AUTOSAR XML (schema 00051)
package /SharedElements/PortInterfaces/ClientServer
  client server interface InProc_OBCSt_SR
    4 x operation:
      OBC00S  # Turn switch sensor position [left, off, right]
      OBC01S  # Turn switch sensor position [left, off, right]
      OBC10S  # Turn switch sensor position [left, off, right]
      OBC11S  # Turn switch sensor position [left, off, right]
package /SharedElements/PortInterfaces/NvData
  nv data interface InProc_OBCErPrmntActvDschrg_SR
    nv-datas:
      4 x data:
        OBC00EPAD  # Turn switch sensor position [left, off, right]
        OBC01EPAD  # Turn switch sensor position [left, off, right]
        OBC10EPAD  # Turn switch sensor position [left, off, right]
        OBC11EPAD  # Turn switch sensor position [left, off, right]
  nv data interface NV_BCBStatDrsn_NVD
    nv-datas:
      data BCBStatDrsn_NvData  # Turn switch sensor position [left, off, right]
package /SharedElements/PortInterfaces/Parameter
  parameter interface GC_ActvDshgStrtTm_PI
    parameter data prototype ADST  # Turn switch sensor position [left, off, right]
package /SharedElements/PortInterfaces/Trigger
  trigger interface TriggerInterface
package /SwComponentTypes/ApplSWC
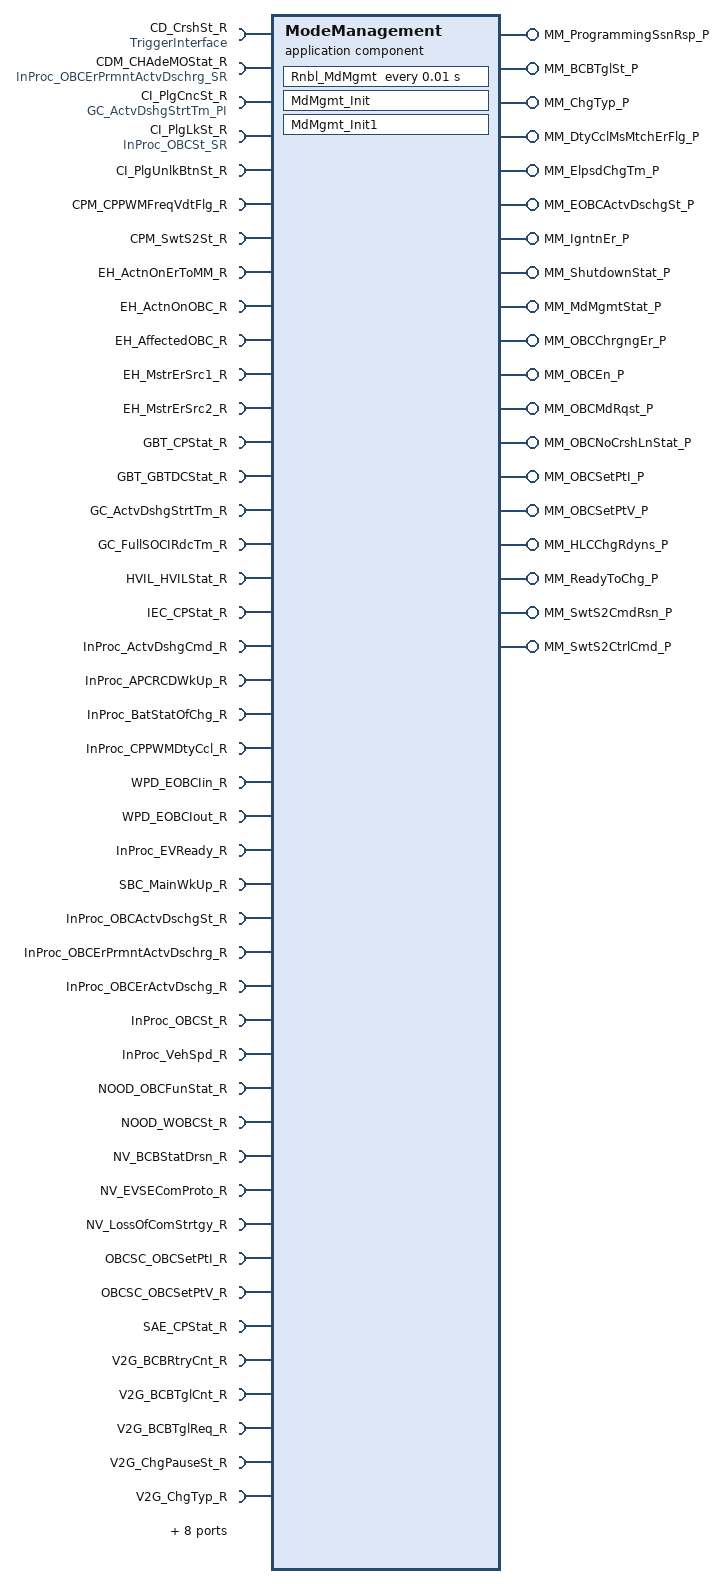
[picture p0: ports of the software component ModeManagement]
  application sw component type ModeManagement
    31 x require port:
      CD_CrshSt_R: required-interface=TriggerInterface
      CDM_CHAdeMOStat_R: required-interface=InProc_OBCErPrmntActvDschrg_SR
      CI_PlgCncSt_R: required-interface=GC_ActvDshgStrtTm_PI
      CI_PlgLkSt_R: required-interface=InProc_OBCSt_SR
      CI_PlgUnlkBtnSt_R
      CPM_CPPWMFreqVdtFlg_R
      CPM_SwtS2St_R
      EH_ActnOnErToMM_R
      EH_ActnOnOBC_R
      EH_AffectedOBC_R
      EH_MstrErSrc1_R
      EH_MstrErSrc2_R
      GBT_CPStat_R
      GBT_GBTDCStat_R
      GC_ActvDshgStrtTm_R
      GC_FullSOCIRdcTm_R
      HVIL_HVILStat_R
      IEC_CPStat_R
      InProc_ActvDshgCmd_R
      InProc_APCRCDWkUp_R
      InProc_BatStatOfChg_R
      InProc_CPPWMDtyCcl_R
      WPD_EOBCIin_R
      WPD_EOBCIout_R
      InProc_EVReady_R
      SBC_MainWkUp_R
      InProc_OBCActvDschgSt_R
      InProc_OBCErPrmntActvDschrg_R
      InProc_OBCErActvDschg_R
      InProc_OBCSt_R
      InProc_VehSpd_R
    19 x provide port:
      MM_ProgrammingSsnRsp_P
      MM_BCBTglSt_P
      MM_ChgTyp_P
      MM_DtyCclMsMtchErFlg_P
      MM_ElpsdChgTm_P
      MM_EOBCActvDschgSt_P
      MM_IgntnEr_P
      MM_ShutdownStat_P
      MM_MdMgmtStat_P
      MM_OBCChrgngEr_P
      MM_OBCEn_P
      MM_OBCMdRqst_P
      MM_OBCNoCrshLnStat_P
      MM_OBCSetPtI_P
      MM_OBCSetPtV_P
      MM_HLCChgRdyns_P
      MM_ReadyToChg_P
      MM_SwtS2CmdRsn_P
      MM_SwtS2CtrlCmd_P
    21 x require port:
      NOOD_OBCFunStat_R
      NOOD_WOBCSt_R
      NV_BCBStatDrsn_R
      NV_EVSEComProto_R
      NV_LossOfComStrtgy_R
      OBCSC_OBCSetPtI_R
      OBCSC_OBCSetPtV_R
      SAE_CPStat_R
      V2G_BCBRtryCnt_R
      V2G_BCBTglCnt_R
      V2G_BCBTglReq_R
      V2G_ChgPauseSt_R
      V2G_ChgTyp_R
      V2G_ComStat_R
      V2G_DLINKEr_R
      V2G_DLINKSt_R
      V2G_EVSEIsltnSt_R
      V2G_EVSEMchngSt_R
      V2G_SwtS2ActnRqst_R
      InProc_EngineSpd_R
      BSWM_ProgrammingSsnRqst_R: required-interface=NV_BCBStatDrsn_NVD
    behavior IB_MdMgmt
      init event MdMgmt_InitEvent: start-on-event=MdMgmt_Init
      init event MdMgmt_InitEvent1: start-on-event=MdMgmt_Init1
      timing event MdMgmt10ms: start-on-event=Rnbl_MdMgmt, period=0.01
      runnable MdMgmt_Init
      runnable MdMgmt_Init1
      runnable Rnbl_MdMgmt
